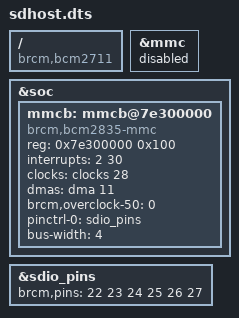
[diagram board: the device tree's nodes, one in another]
/dts-v1/;
/plugin/;

/{
        compatible = "brcm,bcm2711";

        fragment@1{
                target = <&mmc>;
                __overlay__ {
                        status = "disabled";
                };
        };

        fragment@2{
                target = <&soc>;
                __overlay__ {
                        mmcb: mmcb@7e300000 {
                                compatible = "brcm,bcm2835-mmc";
                                reg = <0x7e300000 0x100>;
                                interrupts = <2 30>;
                                clocks = <&clocks 28>;
                                dmas = <&dma 11>;
                                dma-names = "rx-tx";
                                brcm,overclock-50 = <0>;
                                status = "okay";
                                pinctrl-names = "default";
                                pinctrl-0 = <&sdio_pins>;
                                bus-width = <4>;
                        };
                };
        };

        fragment@3 {
                target = <&sdio_pins>;
                __overlay__ {
                        brcm,pins = <22 23 24 25 26 27>;
                };
        };

};
